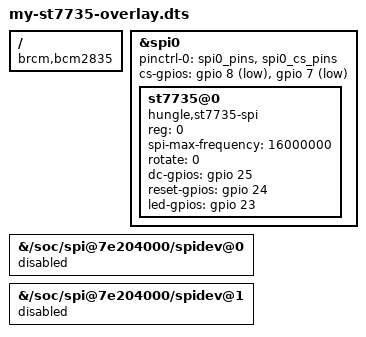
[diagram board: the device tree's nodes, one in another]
/dts-v1/;
/plugin/;

/ {
    compatible = "brcm,bcm2835";

    fragment@0 {
        target = <&spi0>;
        __overlay__ {
            pinctrl-names = "default";
            pinctrl-0 = <&spi0_pins &spi0_cs_pins>;
            cs-gpios = <&gpio 8 1>, <&gpio 7 1>;
            status = "okay";

            #address-cells = <1>;
            #size-cells = <0>;

            st7735@0 {
                compatible = "hungle,st7735-spi";
                reg = <0>;
                spi-max-frequency = <16000000>;
                rotate = <0>;
                dc-gpios = <&gpio 25 0>;
                reset-gpios = <&gpio 24 0>;
                led-gpios = <&gpio 23 0>;
                status = "okay";
            };
        };
    };

    fragment@1 {
        target-path = "/soc/spi@7e204000/spidev@0";
        __overlay__ {
            status = "disabled";
        };
    };

    fragment@2 {
        target-path = "/soc/spi@7e204000/spidev@1";
        __overlay__ {
            status = "disabled";
        };
    };
};
